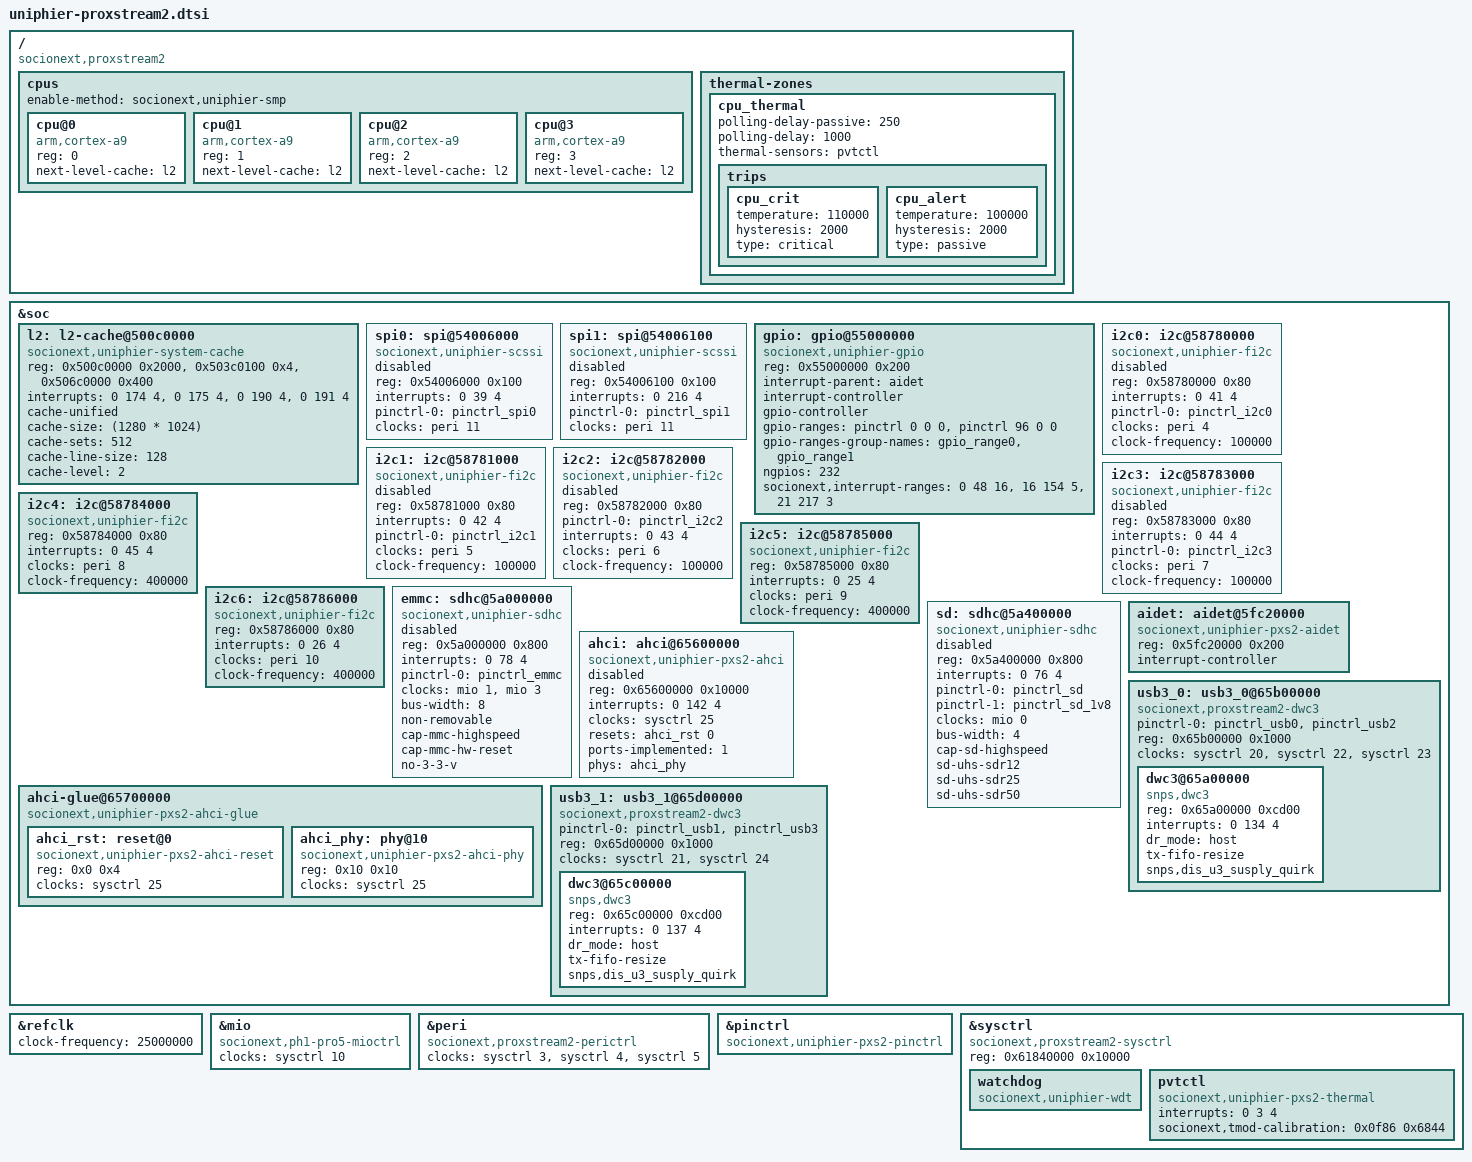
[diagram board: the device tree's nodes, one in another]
// SPDX-License-Identifier: GPL-2.0+ OR MIT
//
// Device Tree Source for UniPhier ProXstream2 SoC
//
// Copyright (C) 2015-2016 Socionext Inc.
//   Author: Masahiro Yamada <yamada.masahiro@socionext.com>

#include "uniphier-common32.dtsi"

/ {
	compatible = "socionext,proxstream2";

	cpus {
		#address-cells = <1>;
		#size-cells = <0>;
		enable-method = "socionext,uniphier-smp";

		cpu@0 {
			device_type = "cpu";
			compatible = "arm,cortex-a9";
			reg = <0>;
			next-level-cache = <&l2>;
		};

		cpu@1 {
			device_type = "cpu";
			compatible = "arm,cortex-a9";
			reg = <1>;
			next-level-cache = <&l2>;
		};

		cpu@2 {
			device_type = "cpu";
			compatible = "arm,cortex-a9";
			reg = <2>;
			next-level-cache = <&l2>;
		};

		cpu@3 {
			device_type = "cpu";
			compatible = "arm,cortex-a9";
			reg = <3>;
			next-level-cache = <&l2>;
		};
	};

	thermal-zones {
		cpu_thermal {
			polling-delay-passive = <250>;	/* 250ms */
			polling-delay = <1000>;		/* 1000ms */
			thermal-sensors = <&pvtctl>;

			trips {
				cpu_crit: cpu_crit {
					temperature = <110000>;	/* 110C */
					hysteresis = <2000>;
					type = "critical";
				};
				cpu_alert: cpu_alert {
					temperature = <100000>;	/* 100C */
					hysteresis = <2000>;
					type = "passive";
				};
			};
		};
	};
};

&soc {
	l2: l2-cache@500c0000 {
		compatible = "socionext,uniphier-system-cache";
		reg = <0x500c0000 0x2000>, <0x503c0100 0x4>, <0x506c0000 0x400>;
		interrupts = <0 174 4>, <0 175 4>, <0 190 4>, <0 191 4>;
		cache-unified;
		cache-size = <(1280 * 1024)>;
		cache-sets = <512>;
		cache-line-size = <128>;
		cache-level = <2>;
	};

	spi0: spi@54006000 {
		compatible = "socionext,uniphier-scssi";
		status = "disabled";
		reg = <0x54006000 0x100>;
		interrupts = <0 39 4>;
		pinctrl-names = "default";
		pinctrl-0 = <&pinctrl_spi0>;
		clocks = <&peri 11>;
	};

	spi1: spi@54006100 {
		compatible = "socionext,uniphier-scssi";
		status = "disabled";
		reg = <0x54006100 0x100>;
		interrupts = <0 216 4>;
		pinctrl-names = "default";
		pinctrl-0 = <&pinctrl_spi1>;
		clocks = <&peri 11>;
	};

	gpio: gpio@55000000 {
		compatible = "socionext,uniphier-gpio";
		reg = <0x55000000 0x200>;
		interrupt-parent = <&aidet>;
		interrupt-controller;
		#interrupt-cells = <2>;
		gpio-controller;
		#gpio-cells = <2>;
		gpio-ranges = <&pinctrl 0 0 0>,
			      <&pinctrl 96 0 0>;
		gpio-ranges-group-names = "gpio_range0",
					  "gpio_range1";
		ngpios = <232>;
		socionext,interrupt-ranges = <0 48 16>, <16 154 5>,
					     <21 217 3>;
	};

	i2c0: i2c@58780000 {
		compatible = "socionext,uniphier-fi2c";
		status = "disabled";
		reg = <0x58780000 0x80>;
		#address-cells = <1>;
		#size-cells = <0>;
		interrupts = <0 41 4>;
		pinctrl-names = "default";
		pinctrl-0 = <&pinctrl_i2c0>;
		clocks = <&peri 4>;
		clock-frequency = <100000>;
	};

	i2c1: i2c@58781000 {
		compatible = "socionext,uniphier-fi2c";
		status = "disabled";
		reg = <0x58781000 0x80>;
		#address-cells = <1>;
		#size-cells = <0>;
		interrupts = <0 42 4>;
		pinctrl-names = "default";
		pinctrl-0 = <&pinctrl_i2c1>;
		clocks = <&peri 5>;
		clock-frequency = <100000>;
	};

	i2c2: i2c@58782000 {
		compatible = "socionext,uniphier-fi2c";
		status = "disabled";
		reg = <0x58782000 0x80>;
		#address-cells = <1>;
		#size-cells = <0>;
		pinctrl-names = "default";
		pinctrl-0 = <&pinctrl_i2c2>;
		interrupts = <0 43 4>;
		clocks = <&peri 6>;
		clock-frequency = <100000>;
	};

	i2c3: i2c@58783000 {
		compatible = "socionext,uniphier-fi2c";
		status = "disabled";
		reg = <0x58783000 0x80>;
		#address-cells = <1>;
		#size-cells = <0>;
		interrupts = <0 44 4>;
		pinctrl-names = "default";
		pinctrl-0 = <&pinctrl_i2c3>;
		clocks = <&peri 7>;
		clock-frequency = <100000>;
	};

	/* chip-internal connection for DMD */
	i2c4: i2c@58784000 {
		compatible = "socionext,uniphier-fi2c";
		reg = <0x58784000 0x80>;
		#address-cells = <1>;
		#size-cells = <0>;
		interrupts = <0 45 4>;
		clocks = <&peri 8>;
		clock-frequency = <400000>;
	};

	/* chip-internal connection for STM */
	i2c5: i2c@58785000 {
		compatible = "socionext,uniphier-fi2c";
		reg = <0x58785000 0x80>;
		#address-cells = <1>;
		#size-cells = <0>;
		interrupts = <0 25 4>;
		clocks = <&peri 9>;
		clock-frequency = <400000>;
	};

	/* chip-internal connection for HDMI */
	i2c6: i2c@58786000 {
		compatible = "socionext,uniphier-fi2c";
		reg = <0x58786000 0x80>;
		#address-cells = <1>;
		#size-cells = <0>;
		interrupts = <0 26 4>;
		clocks = <&peri 10>;
		clock-frequency = <400000>;
	};

	emmc: sdhc@5a000000 {
		compatible = "socionext,uniphier-sdhc";
		status = "disabled";
		reg = <0x5a000000 0x800>;
		interrupts = <0 78 4>;
		pinctrl-names = "default";
		pinctrl-0 = <&pinctrl_emmc>;
		clock-names = "host", "hw-reset";
		clocks = <&mio 1>, <&mio 3>;
		bus-width = <8>;
		non-removable;
		cap-mmc-highspeed;
		cap-mmc-hw-reset;
		no-3-3-v;
	};

	sd: sdhc@5a400000 {
		compatible = "socionext,uniphier-sdhc";
		status = "disabled";
		reg = <0x5a400000 0x800>;
		interrupts = <0 76 4>;
		pinctrl-names = "default", "1.8v";
		pinctrl-0 = <&pinctrl_sd>;
		pinctrl-1 = <&pinctrl_sd_1v8>;
		clock-names = "host";
		clocks = <&mio 0>;
		bus-width = <4>;
		cap-sd-highspeed;
		sd-uhs-sdr12;
		sd-uhs-sdr25;
		sd-uhs-sdr50;
	};

	aidet: aidet@5fc20000 {
		compatible = "socionext,uniphier-pxs2-aidet";
		reg = <0x5fc20000 0x200>;
		interrupt-controller;
		#interrupt-cells = <2>;
	};

	ahci: ahci@65600000 {
		compatible = "socionext,uniphier-pxs2-ahci",
			     "generic-ahci";
		status = "disabled";
		reg = <0x65600000 0x10000>;
		interrupts = <0 142 4>;
		clocks = <&sysctrl 25>;
		resets = <&ahci_rst 0>;
		ports-implemented = <1>;
		phys = <&ahci_phy>;
	};

	ahci-glue@65700000 {
		compatible = "socionext,uniphier-pxs2-ahci-glue",
			     "simple-mfd";
		#address-cells = <1>;
		#size-cells = <1>;
		ranges = <0 0x65700000 0x100>;

		ahci_rst: reset@0 {
			compatible = "socionext,uniphier-pxs2-ahci-reset";
			reg = <0x0 0x4>;
			clock-names = "link";
			clocks = <&sysctrl 25>;
			#reset-cells = <1>;
		};

		ahci_phy: phy@10 {
			compatible = "socionext,uniphier-pxs2-ahci-phy";
			reg = <0x10 0x10>;
			clock-names = "link";
			clocks = <&sysctrl 25>;
			#phy-cells = <0>;
		};
	};

	usb3_0: usb3_0@65b00000 {
		compatible = "socionext,proxstream2-dwc3";
		status = "okay";
		pinctrl-names = "default";
		pinctrl-0 = <&pinctrl_usb0>, <&pinctrl_usb2>;
		reg = <0x65b00000 0x1000>;
		clocks = <&sysctrl 20>,<&sysctrl 22>,<&sysctrl 23>;
		clock-names = "u3clk0", "u3clk1", "u2clk0";
		#address-cells = <1>;
		#size-cells = <1>;
		ranges;
		dwc3@65a00000 {
			compatible = "snps,dwc3";
			reg = <0x65a00000 0xcd00>;
			interrupts = <0 134 4>;
			dr_mode = "host";
			tx-fifo-resize;
			snps,dis_u3_susply_quirk;
		};
	};

	usb3_1: usb3_1@65d00000 {
		compatible = "socionext,proxstream2-dwc3";
		status = "okay";
		pinctrl-names = "default";
		pinctrl-0 = <&pinctrl_usb1>, <&pinctrl_usb3>;
		reg = <0x65d00000 0x1000>;
		clocks = <&sysctrl 21>,<&sysctrl 24>;
		clock-names = "u3clk0", "u2clk0";
		#address-cells = <1>;
		#size-cells = <1>;
		ranges;
		dwc3@65c00000 {
			compatible = "snps,dwc3";
			reg = <0x65c00000 0xcd00>;
			interrupts = <0 137 4>;
			dr_mode = "host";
			tx-fifo-resize;
			snps,dis_u3_susply_quirk;
		};
	};
};

&refclk {
	clock-frequency = <25000000>;
};

&mio {
	compatible = "socionext,ph1-pro5-mioctrl";
	clock-names = "stdmac";
	clocks = <&sysctrl 10>;
};

&peri {
	compatible = "socionext,proxstream2-perictrl";
	clock-names = "uart", "fi2c", "spi";
	clocks = <&sysctrl 3>, <&sysctrl 4>, <&sysctrl 5>;
};

&pinctrl {
	compatible = "socionext,uniphier-pxs2-pinctrl";
};

&sysctrl {
	compatible = "socionext,proxstream2-sysctrl",
		     "simple-mfd", "syscon";
	reg = <0x61840000 0x10000>;

	watchdog {
		compatible = "socionext,uniphier-wdt";
	};

	pvtctl: pvtctl {
		compatible = "socionext,uniphier-pxs2-thermal";
		interrupts = <0 3 4>;
		#thermal-sensor-cells = <0>;
		socionext,tmod-calibration = <0x0f86 0x6844>;
	};
};
